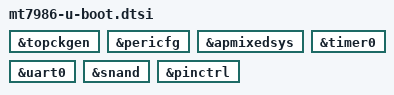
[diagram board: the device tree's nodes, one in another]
// SPDX-License-Identifier: GPL-2.0
/*
 * Copyright (c) 2022 MediaTek Inc.
 * Author: Sam Shih <sam.shih@mediatek.com>
 */

&topckgen {
	u-boot,dm-all;
};

&pericfg {
	u-boot,dm-all;
};

&apmixedsys {
	u-boot,dm-all;
};

&timer0 {
	u-boot,dm-all;
};

&uart0 {
	u-boot,dm-all;
};

&snand {
	u-boot,dm-all;
};

&pinctrl {
	u-boot,dm-all;
};
